# STM32L100C6U6 register map
File version: 1.0
STM32L100C6U6,STM32L100C6U6A,STM32L100R8T6,STM32L100R8T6A,STM32L100RBT6,STM32L100RBT6A,STM32L100RCT6,STM32L151C6T6,STM32L151C6T6A,STM32L151C6U6,STM32L151C6U6A,STM32L151C8T6,STM32L151C8T6A,STM32L151C8U6,STM32L151C8U6A,STM32L151CBT3,STM32L151CBT6,STM32L151CBT6A,STM32L151CBT7,STM32L151CBU3,STM32L151CBU6,STM32L151CBU6A,STM32L151CBU7,STM32L151CCT6,STM32L151CCT7,STM32L151CCU6,STM32L151CCU7,STM32L151QCH6,STM32L151QDH6,STM32L151QEH6,STM32L151R6H6,STM32L151R6H6A,STM32L151R6T6,STM32L151R6T6A,STM32L151R8H6,STM32L151R8H6A,STM32L151R8T6,STM32L151R8T6A,STM32L151RBH3,STM32L151RBH6,STM32L151RBH6A,STM32L151RBH7,STM32L151RBT3,STM32L151RBT6,STM32L151RBT6A,STM32L151RBT7,STM32L151RCT6,STM32L151RCT6A,STM32L151RCY6,STM32L151RDT6,STM32L151RDT7,STM32L151RDY6,STM32L151RDY7,STM32L151RET6,STM32L151UCY3,STM32L151UCY6,STM32L151UCY7,STM32L151V8H6,STM32L151V8H6A,STM32L151V8T6,STM32L151V8T6A,STM32L151VBH3,STM32L151VBH6,STM32L151VBH6A,STM32L151VBH7,STM32L151VBT3,STM32L151VBT6,STM32L151VBT6A,STM32L151VBT7,STM32L151VCH3,STM32L151VCH6,STM32L151VCH7,STM32L151VCT3,STM32L151VCT6,STM32L151VCT6A,STM32L151VCT7,STM32L151VDT6,STM32L151VDT6X,STM32L151VDY6X,STM32L151VET3,STM32L151VET6,STM32L151VET7,STM32L151VEY3,STM32L151VEY6,STM32L151VEY7,STM32L151ZCT6,STM32L151ZDT6,STM32L151ZET6,STM32L152C6T6,STM32L152C6T6A,STM32L152C6U6,STM32L152C6U6A,STM32L152C8T6,STM32L152C8T6A,STM32L152C8U6,STM32L152C8U6A,STM32L152CBT6,STM32L152CBT6A,STM32L152CBU6,STM32L152CBU6A,STM32L152CCT3,STM32L152CCT6,STM32L152CCT7,STM32L152CCU3,STM32L152CCU6,S
Registers are 32-bit, access not given, reset 0x0 unless marked. A register's access mark holds for its fields unless they carry their own. Offsets are from the block's base; lines under a group give offsets from that group; [hi:lo] are bit positions; {n}, {i} and the like mark numbered series; 'fields as' and 'values as' point back to an identical list; <NAME> marks a mode.

## Memory map
0x40000000 TIM2
0x40000400 TIM3
0x40000800 TIM4
0x40000C00 TIM5
0x40001000 TIM6
0x40001400 TIM7
0x40002400 LCD
0x40002800 RTC
0x40002C00 WWDG
0x40003000 IWDG
0x40003800 SPI2
0x40003C00 SPI3
0x40004400 USART2
0x40004800 USART3
0x40004C00 USART4
0x40005000 USART5
0x40005400 I2C1
0x40005800 I2C2
0x40005C00 USBFS
0x40006000 USBFSSRAM512
0x40007000 PWR
0x40007400 DAC
0x40007C00 COMP
0x40007C04 RI
0x40007C5C OPAMP
0x40010000 SYSCFG
0x40010400 EXTI
0x40010800 TIM9
0x40010C00 TIM10
0x40011000 TIM11
0x40012400 ADC
0x40012C00 SDIO
0x40013000 SPI1
0x40013800 USART1
0x40020000 GPIOA
0x40020400 GPIOB
0x40020800 GPIOC
0x40020C00 GPIOD
0x40021000 GPIOE
0x40021400 GPIOH
0x40021800 GPIOF
0x40021C00 GPIOG
0x40023000 CRC
0x40023800 RCC
0x40023C00 FLASH
0x40026000 DMA1
0x40026400 DMA2
0x50060000 AES
0xA0000000 FSMC

## TIM2
Base 0x40000000
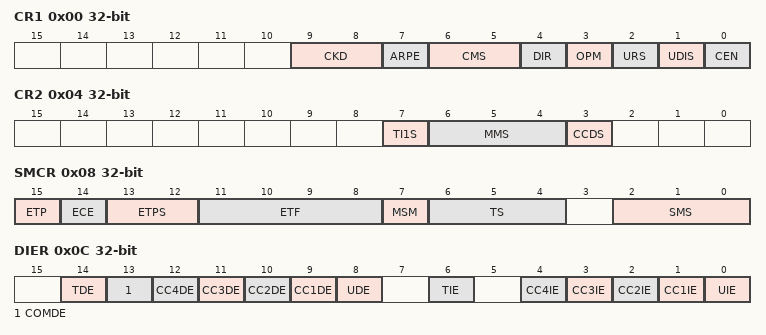
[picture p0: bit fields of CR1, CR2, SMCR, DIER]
0x00 CR1
  [9:8] CKD, [7] ARPE, [6:5] CMS, [4] DIR, [3] OPM, [2] URS, [1] UDIS, [0] CEN
0x04 CR2
  [7] TI1S, [6:4] MMS, [3] CCDS
0x08 SMCR
  [15] ETP, [14] ECE, [13:12] ETPS, [11:8] ETF, [7] MSM, [6:4] TS, [2:0] SMS
0x0C DIER
  [14] TDE, [13] COMDE, [n+8] CC{n}DE (n=1..4), [8] UDE, [6] TIE, [n] CC{n}IE (n=1..4), [0] UIE
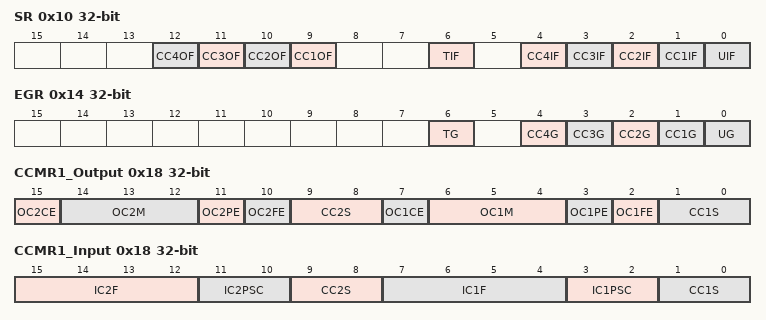
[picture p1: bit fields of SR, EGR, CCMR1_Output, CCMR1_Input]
0x10 SR
  [n+8] CC{n}OF (n=1..4), [6] TIF, [n] CC{n}IF (n=1..4), [0] UIF
0x14 EGR
  [6] TG, [n] CC{n}G (n=1..4), [0] UG
0x18 CCMR1_Output
  [15] OC2CE, [14:12] OC2M, [11] OC2PE, [10] OC2FE, [9:8] CC2S, [7] OC1CE, [6:4] OC1M, [3] OC1PE, [2] OC1FE, [1:0] CC1S
0x18 CCMR1_Input
  [15:12] IC2F, [11:10] IC2PSC, [9:8] CC2S, [7:4] IC1F, [3:2] IC1PSC, [1:0] CC1S
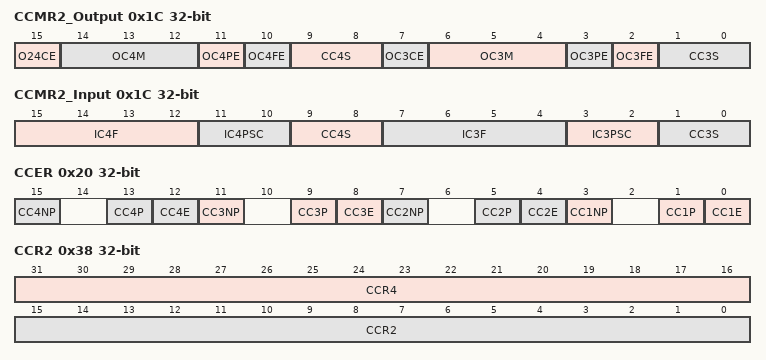
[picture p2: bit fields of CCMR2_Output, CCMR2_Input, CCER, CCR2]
0x1C CCMR2_Output
  [15] O24CE, [14:12] OC4M, [11] OC4PE, [10] OC4FE, [9:8] CC4S, [7] OC3CE, [6:4] OC3M, [3] OC3PE, [2] OC3FE, [1:0] CC3S
0x1C CCMR2_Input
  [15:12] IC4F, [11:10] IC4PSC, [9:8] CC4S, [7:4] IC3F, [3:2] IC3PSC, [1:0] CC3S
0x20 CCER
  [4n-1] CC{n}NP (n=1..4), [4n-3] CC{n}P (n=1..4), [4n-4] CC{n}E (n=1..4)
0x24 CNT
0x28 PSC
  [15:0] PSC
0x2C ARR
0x34 CCR1
0x38 CCR2
  [31:16] CCR4, [15:0] CCR2
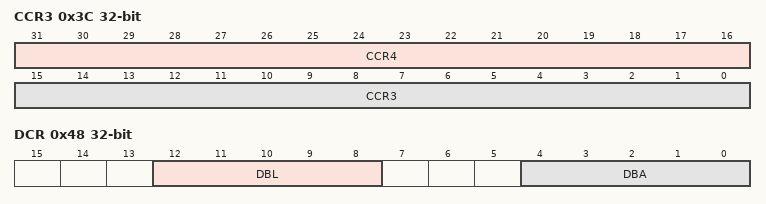
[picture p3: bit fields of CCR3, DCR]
0x3C CCR3
  [31:16] CCR4, [15:0] CCR3
0x40 CCR4
0x48 DCR
  [12:8] DBL, [4:0] DBA
0x4C DMAR
  [15:0] DMAB
0x50 OR
  [0] ITR1_RMP

## TIM3
Base 0x40000400
Registers as TIM2; these are added or differ:
0x50 OR
  [0] ITR2_RMP

## TIM4
Base 0x40000800
Registers as TIM2, without OR.

## TIM5
Base 0x40000C00
Registers as TIM2, without OR.
